# MCU_CTRL_MMR0_CFG0 register map
Vendor: Texas Instruments
Peripheral module from a debugger description file (folder J721S2).
Registers are 32-bit, read-write, reset 0x0 unless marked. A register's access mark holds for its fields unless they carry their own. Offsets are as the file gives them; lines under a group give offsets from that group; [hi:lo] are bit positions; {n}, {i} and the like mark numbered series; 'fields as' and 'values as' point back to an identical list; <NAME> marks a mode.

## MCU_CTRL_MMR0_CFG0 (part 1 of 2)
0x6060 CFG0_MCU_SPI1_CTRL_PROXY
  [0] MCU_SPI1_CTRL_SPI1_LINKDIS_PROXY — Disables direct connection of MCU_SPI1 to SPI3 Field values (others are reserved): 1'b0 - MCU_SPI1 is tied as a slave to SPI3. MCU_SPI1 CLK, DATA1 and CS0 are driven from SPI3, DATA OUT drives SPI3 DATA0 1'b1 - MCU_SPI1 is NOT tied as a slave to SPI3. MCU_SPI1 CLK, DATA0, DATA1 and CS[3:0] are controlled through their respective MCU_SPI1 pins and SPI3 CLK, DATA0, DATA1, and CS[3:0] are controlled through their respective SPI3 pins.
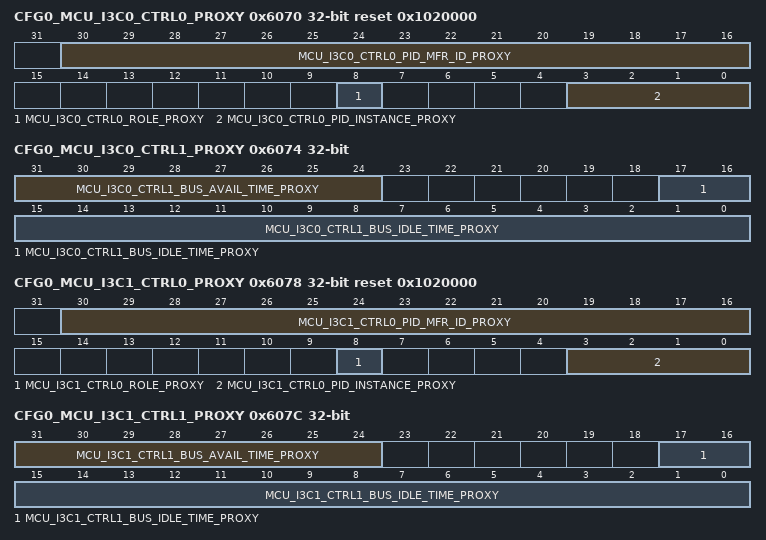
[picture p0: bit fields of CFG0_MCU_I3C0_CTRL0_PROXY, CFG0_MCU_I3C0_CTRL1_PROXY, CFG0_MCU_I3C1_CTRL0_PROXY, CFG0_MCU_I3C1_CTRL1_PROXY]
0x6070 CFG0_MCU_I3C0_CTRL0_PROXY reset 0x1020000
  [30:16] MCU_I3C0_CTRL0_PID_MFR_ID_PROXY — Manufacturer ID This input corresponds to bits[47:33] of the Provisional ID to identify the manufacturer. Defaults to TI value.
  [8] MCU_I3C0_CTRL0_ROLE_PROXY — Master Role 0 - Main master 1 - Secondary master
  [3:0] MCU_I3C0_CTRL0_PID_INSTANCE_PROXY — Provisional ID Instance. This input corresponds to bits[15:12] of the Provisional ID. It is intended to provide a way of differentiating several I3C devices if there would be no other way to have each manufactured device have a unique Provisional ID
0x6074 CFG0_MCU_I3C0_CTRL1_PROXY
  [31:24] MCU_I3C0_CTRL1_BUS_AVAIL_TIME_PROXY — Indicates the number of pclk cycles in the Bus Available condition
  [17:0] MCU_I3C0_CTRL1_BUS_IDLE_TIME_PROXY — Indicates the number of pclk cycles in the Bus Idle condition
0x6078 CFG0_MCU_I3C1_CTRL0_PROXY reset 0x1020000
  [30:16] MCU_I3C1_CTRL0_PID_MFR_ID_PROXY — Manufacturer ID This input corresponds to bits[47:33] of the Provisional ID to identify the manufacturer. Defaults to TI value.
  [8] MCU_I3C1_CTRL0_ROLE_PROXY — Master Role 0 - Main master 1 - Secondary master
  [3:0] MCU_I3C1_CTRL0_PID_INSTANCE_PROXY — Provisional ID Instance. This input corresponds to bits[15:12] of the Provisional ID. It is intended to provide a way of differentiating several I3C devices if there would be no other way to have each manufactured device have a unique Provisional ID
0x607C CFG0_MCU_I3C1_CTRL1_PROXY
  [31:24] MCU_I3C1_CTRL1_BUS_AVAIL_TIME_PROXY — Indicates the number of pclk cycles in the Bus Available condition
  [17:0] MCU_I3C1_CTRL1_BUS_IDLE_TIME_PROXY — Indicates the number of pclk cycles in the Bus Idle condition
0x6080 CFG0_MCU_I2C0_CTRL_PROXY
  [0] MCU_I2C0_CTRL_HS_MCS_EN_PROXY — HS Mode master current source enable. When set, enables the current-source pull-up on the SCL output. Only one master on the I2C bus should enable SCL current sourcing.
0x6084 CFG0_MCU_I2C1_CTRL_PROXY
  [0] MCU_I2C1_CTRL_HS_MCS_EN_PROXY — HS Mode master current source enable. When set, enables the current-source pull-up on the SCL output. Only one master on the I2C bus should enable SCL current sourcing.
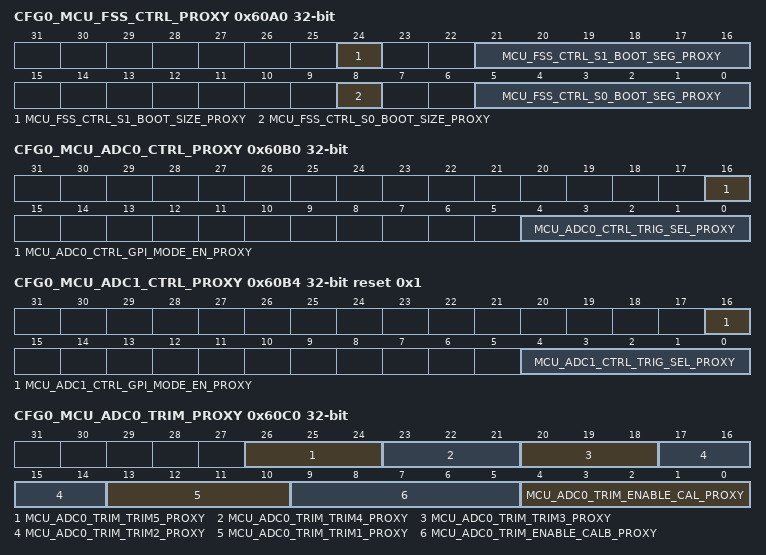
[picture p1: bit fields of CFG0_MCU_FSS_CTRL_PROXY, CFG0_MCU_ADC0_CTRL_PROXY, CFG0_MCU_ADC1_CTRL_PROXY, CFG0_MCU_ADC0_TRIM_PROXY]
0x60A0 CFG0_MCU_FSS_CTRL_PROXY
  [24] MCU_FSS_CTRL_S1_BOOT_SIZE_PROXY — Selects the size of the boot block to be used for the S1 (OSPI1) flash interface 0 - S1 boot size is 64 MB 1 - S1 boot size is 128 MB
  [21:16] MCU_FSS_CTRL_S1_BOOT_SEG_PROXY — Selects the boot block to be used for the S1 (OSPI1) flash interface. If the s1_boot_size is 128 MB then only bits [4:0] of this field are used. Care must be taken to account for the address translation as to not fall off or wrap the address of the flash. (e.g. if both ECC and authentication are enabled for 64 MB boot, the highest valid block number is 49, as sector 50 is only .2M Bytes in size.) 6'h00 - Use block 0 6'h01 - Use block 1 : 6'h3F - Use block 63
  [8] MCU_FSS_CTRL_S0_BOOT_SIZE_PROXY — Selects the size of the boot block to be used for the S0 (OSPI0 or Hyperbus) flash interface 0 - S0 boot size is 64 MB 1 - S0 boot size is 128 MB
  [5:0] MCU_FSS_CTRL_S0_BOOT_SEG_PROXY — Selects the boot block to be used for the S0 (OSPI0 or Hyperbus) flash interface. If the s0_boot_size is 128 MB then only bits [4:0] of this field are used. Care must be taken to account for the address translation as to not fall off or wrap the address of the flash. (e.g. if both ECC and authentication are enabled for 64 MB boot, the highest valid block number is 49, as sector 50 is only .2M Bytes in size.) 6'h00 - Use block 0 6'h01 - Use block 1 : 6'h3F - Use block 63
0x60B0 CFG0_MCU_ADC0_CTRL_PROXY
  [16] MCU_ADC0_CTRL_GPI_MODE_EN_PROXY — Enables MCU_ADC0 data pins to be used as general purpose inputs when set. This signal is tied to the en_dig_test input of MCU_ADC0
  [4:0] MCU_ADC0_CTRL_TRIG_SEL_PROXY — Selects the source of the ADC hardware event trigger Field values (others are reserved): 5'b00000 - MCU_ADC_EXT_TRIGGER0 pin 5'b00001 - MCU_ADC_EXT_TRIGGER1 pin 5'b00010 - eHRPWM SOCA event 5'b00011 - eHRPWM SOCB event 5'b00100 - MCU Timer0 PWM output 5'b00101 - MCU Timer1 PWM output 5'b00110 - MCU Timer2 PWM output 5'b00111 - MCU Timer3 PWM output 5'b01000 - Timer0 PWM output 5'b01001 - Timer1 PWM output 5'b01010 - Timer2 PWM output 5'b01011 - Timer3 PWM output 5'b01100 - Timer4 PWM output 5'b01101 - Timer5 PWM output 5'b01110 - Timer6 PWM output 5'b01111 - Timer7 PWM output 5'b10000 - Timer8 PWM output 5'b10001 - Timer9 PWM output 5'b10010 - Timer10 PWM output 5'b10011 - Timer11 PWM output undefined - undefined 5'b10101 - Reserved (tied 1'b0) undefined - undefined 5'b10110 - Reserved (tied 1'b0) undefined - undefined 5'b10111 - Reserved (tied 1'b0) undefined - undefined 5'b11000 - Reserved (tied 1'b0) 5'b11000 - MCU Timer4 PWM output 5'b11001 - MCU Timer5 PWM output 5'b11010 - MCU Timer6 PWM output 5'b11011 - MCU Timer7 PWM output 5'b11100 - MCU Timer8 PWM output 5'b11101 - MCU Timer9 PWM output 5'b11110 - Reserved (tied 1'b0) 5'b11111 - Reserved (tied 1'b0)
0x60B4 CFG0_MCU_ADC1_CTRL_PROXY reset 0x1
  [16] MCU_ADC1_CTRL_GPI_MODE_EN_PROXY — Enables MCU_ADC1 data pins to be used as general purpose inputs when set. This signal is tied to the en_dig_test input of MCU_ADC1
  [4:0] MCU_ADC1_CTRL_TRIG_SEL_PROXY — Selects the source of the ADC hardware event trigger Field values (others are reserved): 5'b00000 - MCU_ADC_EXT_TRIGGER0 pin 5'b00001 - MCU_ADC_EXT_TRIGGER1 pin 5'b00010 - eHRPWM SOCA event 5'b00011 - eHRPWM SOCB event 5'b00100 - MCU Timer0 PWM output 5'b00101 - MCU Timer1 PWM output 5'b00110 - MCU Timer2 PWM output 5'b00111 - MCU Timer3 PWM output 5'b01000 - Timer0 PWM output 5'b01001 - Timer1 PWM output 5'b01010 - Timer2 PWM output 5'b01011 - Timer3 PWM output 5'b01100 - Timer4 PWM output 5'b01101 - Timer5 PWM output 5'b01110 - Timer6 PWM output 5'b01111 - Timer7 PWM output 5'b10000 - Timer8 PWM output 5'b10001 - Timer9 PWM output 5'b10010 - Timer10 PWM output 5'b10011 - Timer11 PWM output undefined - undefined 5'b10101 - Reserved (tied 1'b0) undefined - undefined 5'b10110 - Reserved (tied 1'b0) undefined - undefined undefined - undefined 5'b11000 - MCU Timer4 PWM output 5'b11001 - MCU Timer5 PWM output 5'b11010 - MCU Timer6 PWM output 5'b11011 - MCU Timer7 PWM output 5'b11100 - MCU Timer8 PWM output 5'b11101 - MCU Timer9 PWM output 5'b11110 - Reserved (tied 1'b0) 5'b11111 - Reserved (tied 1'b0)
0x60C0 CFG0_MCU_ADC0_TRIM_PROXY
  [26:24] MCU_ADC0_TRIM_TRIM5_PROXY — Trim value for C5 0.37 fF to 3.2fF in ~0.37fF increments
  [23:21] MCU_ADC0_TRIM_TRIM4_PROXY — Trim value for C4 0.37 fF to 3.2fF in ~0.37fF increments
  [20:18] MCU_ADC0_TRIM_TRIM3_PROXY — Trim value for C3 0.37 fF to 3.2fF in ~0.37fF increments
  [17:14] MCU_ADC0_TRIM_TRIM2_PROXY — Trim value for C2 0.37 fF to 6.4fF in ~0.37fF increments
  [13:10] MCU_ADC0_TRIM_TRIM1_PROXY — Trim value for C1 0.37 fF to 6.4fF in ~0.37fF increments
  [9:5] MCU_ADC0_TRIM_ENABLE_CALB_PROXY — Reserved. This bitfield no longer used
  [4:0] MCU_ADC0_TRIM_ENABLE_CAL_PROXY — Reserved. This bitfield no longer used
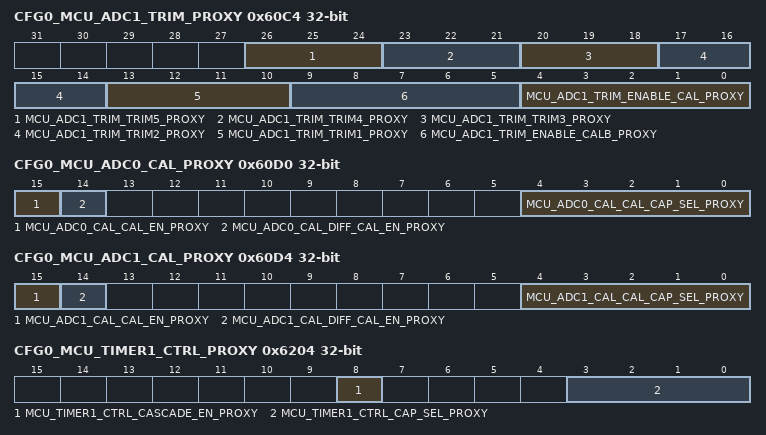
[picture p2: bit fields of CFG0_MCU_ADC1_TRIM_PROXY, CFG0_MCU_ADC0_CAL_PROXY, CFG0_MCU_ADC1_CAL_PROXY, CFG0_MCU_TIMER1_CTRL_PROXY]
0x60C4 CFG0_MCU_ADC1_TRIM_PROXY
  [26:24] MCU_ADC1_TRIM_TRIM5_PROXY — Trim value for C5 0.37 fF to 3.2fF in ~0.37fF increments
  [23:21] MCU_ADC1_TRIM_TRIM4_PROXY — Trim value for C4 0.37 fF to 3.2fF in ~0.37fF increments
  [20:18] MCU_ADC1_TRIM_TRIM3_PROXY — Trim value for C3 0.37 fF to 3.2fF in ~0.37fF increments
  [17:14] MCU_ADC1_TRIM_TRIM2_PROXY — Trim value for C2 0.37 fF to 6.4fF in ~0.37fF increments
  [13:10] MCU_ADC1_TRIM_TRIM1_PROXY — Trim value for C1 0.37 fF to 6.4fF in ~0.37fF increments
  [9:5] MCU_ADC1_TRIM_ENABLE_CALB_PROXY — Reserved. This bitfield no longer used
  [4:0] MCU_ADC1_TRIM_ENABLE_CAL_PROXY — Reserved. This bitfield no longer used
0x60D0 CFG0_MCU_ADC0_CAL_PROXY
  [15] MCU_ADC0_CAL_CAL_EN_PROXY — Enable single-ended calibration Set to 1 to begin single-ended calibration
  [14] MCU_ADC0_CAL_DIFF_CAL_EN_PROXY — Enable differential calibration Set to 1 to begin differential calibration
  [4:0] MCU_ADC0_CAL_CAL_CAP_SEL_PROXY — Select capacitor for calibration Bits correspond to C5:C1 Field values (others are reserved): 5'b00000 - None 5'b00001 - Select C1 5'b00010 - Select C2 5'b00100 - Select C3 5'b01000 - Select C4 5'b10000 - Select C5
0x60D4 CFG0_MCU_ADC1_CAL_PROXY
  [15] MCU_ADC1_CAL_CAL_EN_PROXY — Enable single-ended calibration Set to 1 to begin single-ended calibration
  [14] MCU_ADC1_CAL_DIFF_CAL_EN_PROXY — Enable differential calibration Set to 1 to begin differential calibration
  [4:0] MCU_ADC1_CAL_CAL_CAP_SEL_PROXY — Select capacitor for calibration Bits correspond to C5:C1 Field values (others are reserved): 5'b00000 - None 5'b00001 - Select C1 5'b00010 - Select C2 5'b00100 - Select C3 5'b01000 - Select C4 5'b10000 - Select C5
0x6200 CFG0_MCU_TIMER0_CTRL_PROXY
  [3:0] MCU_TIMER0_CTRL_CAP_SEL_PROXY — Selects the MCU_TIMERIO input pin for capture input signal. This control is only used when TIMER0 is configured for capture operation. Field values (others are reserved): 4'b0000 - Use MCU_TIMER_IO0 pin 4'b0001 - Use MCU_TIMER_IO1 pin 4'b0010 - Use MCU_TIMER_IO2 pin 4'b0011 - Use MCU_TIMER_IO3 pin 4'b0100 - Use MCU_TIMER_IO4 pin 4'b0101 - Use MCU_TIMER_IO5 pin 4'b0110 - Use MCU_TIMER_IO6 pin 4'b0111 - Use MCU_TIMER_IO7 pin 4'b1000 - Use MCU_TIMER_IO8 pin 4'b1001 - Use MCU_TIMER_IO9 pin
0x6204 CFG0_MCU_TIMER1_CTRL_PROXY
  [8] MCU_TIMER1_CTRL_CASCADE_EN_PROXY — When set, enables cascading of MCU_TIMER1 to MCU_TIMER0
  [3:0] MCU_TIMER1_CTRL_CAP_SEL_PROXY — Selects the MCU_TIMERIO input pin for capture input signal. This control is only used when TIMER1 is configured for capture operation. Field values (others are reserved): 4'b0000 - Use MCU_TIMER_IO0 pin 4'b0001 - Use MCU_TIMER_IO1 pin 4'b0010 - Use MCU_TIMER_IO2 pin 4'b0011 - Use MCU_TIMER_IO3 pin 4'b0100 - Use MCU_TIMER_IO4 pin 4'b0101 - Use MCU_TIMER_IO5 pin 4'b0110 - Use MCU_TIMER_IO6 pin 4'b0111 - Use MCU_TIMER_IO7 pin 4'b1000 - Use MCU_TIMER_IO8 pin 4'b1001 - Use MCU_TIMER_IO9 pin
0x6208 CFG0_MCU_TIMER2_CTRL_PROXY
  [3:0] MCU_TIMER2_CTRL_CAP_SEL_PROXY — Selects the MCU_TIMERIO input pin for capture input signal. This control is only used when TIMER2 is configured for capture operation. Field values (others are reserved): 4'b0000 - Use MCU_TIMER_IO0 pin 4'b0001 - Use MCU_TIMER_IO1 pin 4'b0010 - Use MCU_TIMER_IO2 pin 4'b0011 - Use MCU_TIMER_IO3 pin 4'b0100 - Use MCU_TIMER_IO4 pin 4'b0101 - Use MCU_TIMER_IO5 pin 4'b0110 - Use MCU_TIMER_IO6 pin 4'b0111 - Use MCU_TIMER_IO7 pin 4'b1000 - Use MCU_TIMER_IO8 pin 4'b1001 - Use MCU_TIMER_IO9 pin
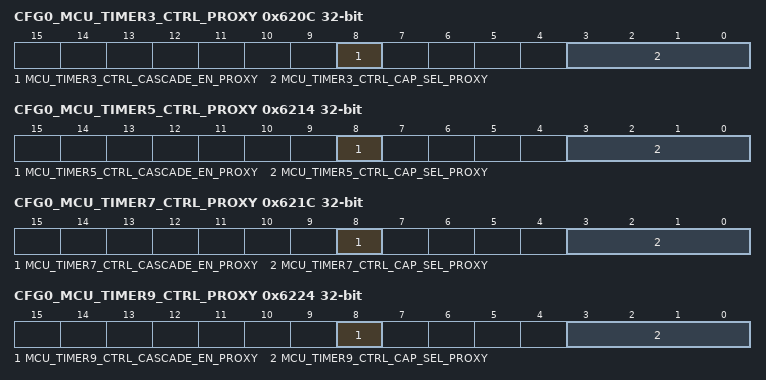
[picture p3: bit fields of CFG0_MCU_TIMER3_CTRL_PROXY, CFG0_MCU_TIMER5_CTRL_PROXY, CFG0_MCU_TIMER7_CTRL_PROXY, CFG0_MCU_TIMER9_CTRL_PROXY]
0x620C CFG0_MCU_TIMER3_CTRL_PROXY
  [8] MCU_TIMER3_CTRL_CASCADE_EN_PROXY — When set, enables cascading of MCU_TIMER3 to MCU_TIMER2
  [3:0] MCU_TIMER3_CTRL_CAP_SEL_PROXY — Selects the MCU_TIMERIO input pin for capture input signal. This control is only used when TIMER3 is configured for capture operation. Field values (others are reserved): 4'b0000 - Use MCU_TIMER_IO0 pin 4'b0001 - Use MCU_TIMER_IO1 pin 4'b0010 - Use MCU_TIMER_IO2 pin 4'b0011 - Use MCU_TIMER_IO3 pin 4'b0100 - Use MCU_TIMER_IO4 pin 4'b0101 - Use MCU_TIMER_IO5 pin 4'b0110 - Use MCU_TIMER_IO6 pin 4'b0111 - Use MCU_TIMER_IO7 pin 4'b1000 - Use MCU_TIMER_IO8 pin 4'b1001 - Use MCU_TIMER_IO9 pin
0x6210 CFG0_MCU_TIMER4_CTRL_PROXY
  [3:0] MCU_TIMER4_CTRL_CAP_SEL_PROXY — Selects the MCU_TIMERIO input pin for capture input signal. This control is only used when TIMER4 is configured for capture operation. Field values (others are reserved): 4'b0000 - Use MCU_TIMER_IO0 pin 4'b0001 - Use MCU_TIMER_IO1 pin 4'b0010 - Use MCU_TIMER_IO2 pin 4'b0011 - Use MCU_TIMER_IO3 pin 4'b0100 - Use MCU_TIMER_IO4 pin 4'b0101 - Use MCU_TIMER_IO5 pin 4'b0110 - Use MCU_TIMER_IO6 pin 4'b0111 - Use MCU_TIMER_IO7 pin 4'b1000 - Use MCU_TIMER_IO8 pin 4'b1001 - Use MCU_TIMER_IO9 pin
0x6214 CFG0_MCU_TIMER5_CTRL_PROXY
  [8] MCU_TIMER5_CTRL_CASCADE_EN_PROXY — When set, enables cascading of MCU_TIMER5 to MCU_TIMER4
  [3:0] MCU_TIMER5_CTRL_CAP_SEL_PROXY — Selects the MCU_TIMERIO input pin for capture input signal. This control is only used when TIMER5 is configured for capture operation. Field values (others are reserved): 4'b0000 - Use MCU_TIMER_IO0 pin 4'b0001 - Use MCU_TIMER_IO1 pin 4'b0010 - Use MCU_TIMER_IO2 pin 4'b0011 - Use MCU_TIMER_IO3 pin 4'b0100 - Use MCU_TIMER_IO4 pin 4'b0101 - Use MCU_TIMER_IO5 pin 4'b0110 - Use MCU_TIMER_IO6 pin 4'b0111 - Use MCU_TIMER_IO7 pin 4'b1000 - Use MCU_TIMER_IO8 pin 4'b1001 - Use MCU_TIMER_IO9 pin
0x6218 CFG0_MCU_TIMER6_CTRL_PROXY
  [3:0] MCU_TIMER6_CTRL_CAP_SEL_PROXY — Selects the MCU_TIMERIO input pin for capture input signal. This control is only used when TIMER6 is configured for capture operation. Field values (others are reserved): 4'b0000 - Use MCU_TIMER_IO0 pin 4'b0001 - Use MCU_TIMER_IO1 pin 4'b0010 - Use MCU_TIMER_IO2 pin 4'b0011 - Use MCU_TIMER_IO3 pin 4'b0100 - Use MCU_TIMER_IO4 pin 4'b0101 - Use MCU_TIMER_IO5 pin 4'b0110 - Use MCU_TIMER_IO6 pin 4'b0111 - Use MCU_TIMER_IO7 pin 4'b1000 - Use MCU_TIMER_IO8 pin 4'b1001 - Use MCU_TIMER_IO9 pin
0x621C CFG0_MCU_TIMER7_CTRL_PROXY
  [8] MCU_TIMER7_CTRL_CASCADE_EN_PROXY — When set, enables cascading of MCU_TIMER7 to MCU_TIMER6
  [3:0] MCU_TIMER7_CTRL_CAP_SEL_PROXY — Selects the MCU_TIMERIO input pin for capture input signal. This control is only used when TIMER7 is configured for capture operation. Field values (others are reserved): 4'b0000 - Use MCU_TIMER_IO0 pin 4'b0001 - Use MCU_TIMER_IO1 pin 4'b0010 - Use MCU_TIMER_IO2 pin 4'b0011 - Use MCU_TIMER_IO3 pin 4'b0100 - Use MCU_TIMER_IO4 pin 4'b0101 - Use MCU_TIMER_IO5 pin 4'b0110 - Use MCU_TIMER_IO6 pin 4'b0111 - Use MCU_TIMER_IO7 pin 4'b1000 - Use MCU_TIMER_IO8 pin 4'b1001 - Use MCU_TIMER_IO9 pin
0x6220 CFG0_MCU_TIMER8_CTRL_PROXY
  [3:0] MCU_TIMER8_CTRL_CAP_SEL_PROXY — Selects the MCU_TIMERIO input pin for capture input signal. This control is only used when TIMER8 is configured for capture operation. Field values (others are reserved): 4'b0000 - Use MCU_TIMER_IO0 pin 4'b0001 - Use MCU_TIMER_IO1 pin 4'b0010 - Use MCU_TIMER_IO2 pin 4'b0011 - Use MCU_TIMER_IO3 pin 4'b0100 - Use MCU_TIMER_IO4 pin 4'b0101 - Use MCU_TIMER_IO5 pin 4'b0110 - Use MCU_TIMER_IO6 pin 4'b0111 - Use MCU_TIMER_IO7 pin 4'b1000 - Use MCU_TIMER_IO8 pin 4'b1001 - Use MCU_TIMER_IO9 pin
0x6224 CFG0_MCU_TIMER9_CTRL_PROXY
  [8] MCU_TIMER9_CTRL_CASCADE_EN_PROXY — When set, enables cascading of MCU_TIMER9 to MCU_TIMER8
  [3:0] MCU_TIMER9_CTRL_CAP_SEL_PROXY — Selects the MCU_TIMERIO input pin for capture input signal. This control is only used when TIMER9 is configured for capture operation. Field values (others are reserved): 4'b0000 - Use MCU_TIMER_IO0 pin 4'b0001 - Use MCU_TIMER_IO1 pin 4'b0010 - Use MCU_TIMER_IO2 pin 4'b0011 - Use MCU_TIMER_IO3 pin 4'b0100 - Use MCU_TIMER_IO4 pin 4'b0101 - Use MCU_TIMER_IO5 pin 4'b0110 - Use MCU_TIMER_IO6 pin 4'b0111 - Use MCU_TIMER_IO7 pin 4'b1000 - Use MCU_TIMER_IO8 pin 4'b1001 - Use MCU_TIMER_IO9 pin
{0x6280+4i} CFG0_MCU_TIMERIO{i}_CTRL_PROXY reset 0xF (i=0..9)
  [3:0] MCU_TIMERIO{i}_CTRL_OUT_SEL_PROXY — Selects the source of the MCU_TIMERIO{i} output Field values (others are reserved): 4'b0000 - MCU_TIMERIO{i} is driven by MCU_TIMER0 output 4'b0001 - MCU_TIMERIO{i} is driven by MCU_TIMER1 output 4'b0010 - MCU_TIMERIO{i} is driven by MCU_TIMER2 output 4'b0011 - MCU_TIMERIO{i} is driven by MCU_TIMER3 output 4'b0100 - MCU_TIMERIO{i} is driven by MCU_TIMER4 output 4'b0101 - MCU_TIMERIO{i} is driven by MCU_TIMER5 output 4'b0110 - MCU_TIMERIO{i} is driven by MCU_TIMER6 output 4'b0111 - MCU_TIMERIO{i} is driven by MCU_TIMER7 output 4'b1000 - MCU_TIMERIO{i} is driven by MCU_TIMER8 output 4'b1001 - MCU_TIMERIO{i} is driven by MCU_TIMER9 output 4'b1010 - MCU_TIMERIO{i} is driven low 4'b1011 - MCU_TIMERIO{i} is driven high 4'b1100 - MCU_TIMERIO{i} is driven low 4'b1101 - MCU_TIMERIO{i} is driven high 4'b1110 - MCU_TIMERIO{i} is driven low 4'b1111 - MCU_TIMERIO{i} is driven high
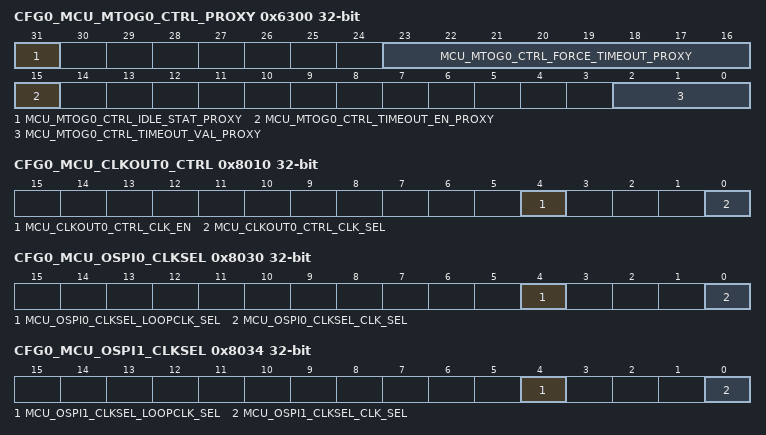
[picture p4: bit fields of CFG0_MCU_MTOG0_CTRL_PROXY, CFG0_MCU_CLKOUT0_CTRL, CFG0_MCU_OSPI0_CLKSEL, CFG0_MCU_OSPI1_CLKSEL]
0x6300 CFG0_MCU_MTOG0_CTRL_PROXY access per field
  [31] MCU_MTOG0_CTRL_IDLE_STAT_PROXY ro — Idle status When high, indicates MTOG0 is idle.
  [23:16] MCU_MTOG0_CTRL_FORCE_TIMEOUT_PROXY rw — Force Timeout Forces a flush of the interface transactions. This bitfield is only relevant if timeout_en=1. After forcing a timeout by writing the encoded value, the force_timeout and timeout_en bitfields must be cleared to clear the timeout before re-enabling the gasket. 8'h95 - Force a gasket timeout All others - Normal operation
  [15] MCU_MTOG0_CTRL_TIMEOUT_EN_PROXY rw — Timeout Enable 1'b0 - Disable the gasket. Clear the interrupt and reset the counter 1'b1 - Enable the timeout gasket functions
  [2:0] MCU_MTOG0_CTRL_TIMEOUT_VAL_PROXY rw — Gasket Timeout Value Selects the number of clock cycles before the interface is considered to have timed out Field values (others are reserved): 3'b000 - 1024 clock cycles 3'b001 - 4096 clock cycles 3'b010 - 16,384 clock cycles 3'b011 - 65,536 clock cycles 3'b100 - 262,144 clock cycles 3'b101 - 1,048,576 clock cycles 3'b110 - 2,097,152 clock cycles 3'b111 - 4,194,303 clock cycles
{0x7100+4i} CFG0_CLAIMREG_P1_R{i} (i=0..6)
  [31:0] CLAIMREG_P1_R{i} — Claim bits for Partition 1
0x8010 CFG0_MCU_CLKOUT0_CTRL
  [4] MCU_CLKOUT0_CTRL_CLK_EN — When set, enables MCU_CLKOUT0 output
  [0] MCU_CLKOUT0_CTRL_CLK_SEL — Selects MCU_CLKOUT0 clock source 1'b0 - RGMII_MHZ_50_CLK (50 MHz) 1'b1 -RGMII_MHZ_50_CLK / 2 (25 MHz)
0x8018 CFG0_MCU_EFUSE_CLKSEL
  [0] MCU_EFUSE_CLKSEL_CLK_SEL — Selects the clock source Field values (others are reserved): 1'b0 - EFUSE_CLK (HFOSC0_CLKOUT or CLK_12M_RC) 1'b1 - MCU_SYSCLK0 / 8
0x8020 CFG0_MCU_MCAN0_CLKSEL
  [1:0] MCU_MCAN0_CLKSEL_CLK_SEL — MCU_MCAN MCAN_CLK selection 2'b00 - MCU_PLL2_HSDIV3_CLKOUT 2'b01 - MCU_EXT_REFCLK0 2'b10 - MCU_PLL1_HSDIV2_CLKOUT 2'b11 - HFOSC0_CLKOUT
0x8024 CFG0_MCU_MCAN1_CLKSEL
  [1:0] MCU_MCAN1_CLKSEL_CLK_SEL — MCU_MCAN MCAN_CLK selection 2'b00 - MCU_PLL2_HSDIV3_CLKOUT 2'b01 - MCU_EXT_REFCLK0 2'b10 - MCU_PLL1_HSDIV2_CLKOUT 2'b11 - HFOSC0_CLKOUT
0x8030 CFG0_MCU_OSPI0_CLKSEL
  [4] MCU_OSPI0_CLKSEL_LOOPCLK_SEL — OBSPI0 Loopback clock source 1'b0 - OSPI_DQS external pin (external) 1'b1 - OSPI_LBCLKO output (internal)
  [0] MCU_OSPI0_CLKSEL_CLK_SEL — OSPI0 reference clock selection 1'b0 - MCU_PLL1_HSDIV4_CLKOUT 1'b1 - MCU_PLL2_HSDIV4_CLKOUT
0x8034 CFG0_MCU_OSPI1_CLKSEL
  [4] MCU_OSPI1_CLKSEL_LOOPCLK_SEL — OBSPI1 Loopback clock source 1'b0 - OSPI_DQS external pin (external) 1'b1 - OSPI_LBCLKO output (internal)
  [0] MCU_OSPI1_CLKSEL_CLK_SEL — OSPI1 reference clock selection 1'b0 - MCU_PLL1_HSDIV4_CLKOUT 1'b1 - MCU_PLL2_HSDIV4_CLKOUT
0x8040 CFG0_MCU_ADC0_CLKSEL
  [1:0] MCU_ADC0_CLKSEL_CLK_SEL — Selects the sampling clock source for ADC0 Field values (others are reserved): 2'b00 - HFOSC0_CLKOUT 2'b01 - MCU_PLL1_HSDIV1_CLKOUT1 2'b10 - MCU_PLL0_HSDIV1_CLKOUT1 2'b11 - MCU_EXT_REFCLK0
0x8044 CFG0_MCU_ADC1_CLKSEL
  [1:0] MCU_ADC1_CLKSEL_CLK_SEL — Selects the sampling clock source for ADC1 Field values (others are reserved): 2'b00 - HFOSC0_CLKOUT 2'b01 - MCU_PLL1_HSDIV1_CLKOUT1 2'b10 - MCU_PLL0_HSDIV1_CLKOUT1 2'b11 - MCU_EXT_REFCLK0
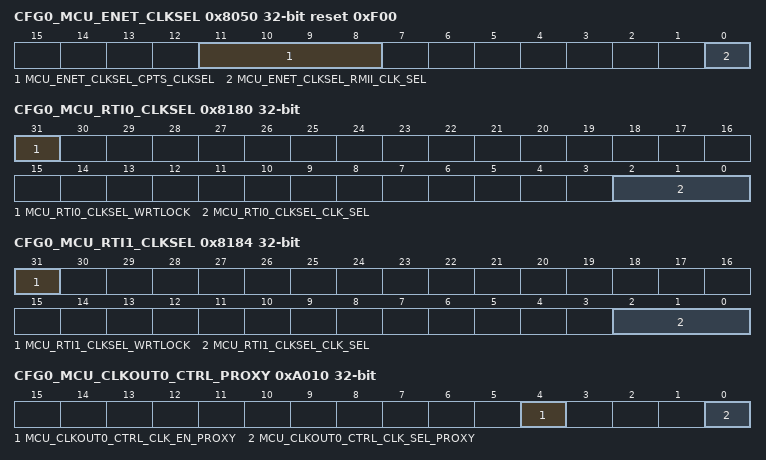
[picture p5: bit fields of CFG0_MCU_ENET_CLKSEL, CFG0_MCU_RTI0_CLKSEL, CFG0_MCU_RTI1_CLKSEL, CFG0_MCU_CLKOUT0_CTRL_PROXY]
0x8050 CFG0_MCU_ENET_CLKSEL reset 0xF00
  [11:8] MCU_ENET_CLKSEL_CPTS_CLKSEL — Selects the clock source for the CPSW2x Ethernet switch Common Platform Time Stamp module Field values (others are reserved): 4'b0000 - MAIN_PLL3_HSDIV1_CLKOUT 4'b0001 - MAIN_PLL0_HSDIV6_CLKOUT 4'b0010 - MCU_CPTS_REF_CLK (pin) 4'b0011 - CPTS_RFT_CLK (pin) 4'b0100 - MCU_EXT_REFCLK0 (pin) 4'b0101 - EXT_REFCLK1 (pin) 4'b0110 - SERDES0_IP2_LN0_TXMCLK 4'b0111 - SERDES0_IP2_LN1_TXMCLK undefined - undefined 4'b1000 - SERDES0_IP2_LN2_TXMCLK undefined - undefined 4'b1001 - SERDES0_IP2_LN3_TXMCLK undefined - undefined undefined - undefined undefined - undefined 4'b1010 - SERDES1_IP2_LN0_TXMCLK undefined - undefined undefined - undefined undefined - undefined 4'b1011 - SERDES1_IP2_LN1_TXMCLK undefined - undefined undefined - undefined undefined - undefined 4'b1100 - SERDES1_IP2_LN2_TXMCLK undefined - undefined undefined - undefined undefined - undefined 4'b1101 - SERDES1_IP2_LN3_TXMCLK 4'b1110 - MCU_PLL2_HSDIV1_CLKOUT undefined - undefined 4'b1111 - MAIN_SYSCLK0 / 2
  [0] MCU_ENET_CLKSEL_RMII_CLK_SEL — Selects the rmii clock (rmii_mhz_50_clk) source. This defaults to the internal 50 MHz clock source for proper clockstop operation 1'b0 - MCU_PLL2_HSDIV0_CLKOUT / 5 1'b1 - MCU_RMII_REFCLK (pin)
0x8080 CFG0_MCU_R5_CORE0_CLKSEL
  [0] MCU_R5_CORE0_CLKSEL_CLK_SEL — Selects the Core 0 functional clock and mcu/interface clock ratio. Note, this value must only be changed when the MCU R5 is powered off or in WFI 1'b0 - Use MCU_SYSCLK0. MCU/interface is 3:1 clock ratio 1'b1 - Use MCU_SYSCLK0/3. MCU/interface is 1:1 clock ratio
0x8084 CFG0_MCU_R5_CORE1_CLKSEL
  [0] MCU_R5_CORE1_CLKSEL_CLK_SEL — Selects the Core 1 functional clock and mcu/interface clock ratio. Note, this value must only be changed when the MCU R5 is powered off or in WFI 1'b0 - Use MCU_SYSCLK0. MCU/interface is 3:1 clock ratio 1'b1 - Use MCU_SYSCLK0/3. MCU/interface is 1:1 clock ratio
{0x8100+4i} CFG0_MCU_TIMER{i}_CLKSEL (i=0..9)
  [2:0] MCU_TIMER{i}_CLKSEL_CLK_SEL — Timer functional clock input select mux control Field values (others are reserved): 3'b000 - HFOSC0_CLKOUT 3'b001 - MCU_SYSCLK0 / 4 3'b010 - CLK_12M_RC 3'b011 - MCU_PLL2_HSDIV2_CLKOUT 3'b100 - MCU_EXT_REFCLK0 3'b101 - LFXOSC_CLKOUT 3'b110 - CPSW_GENF0 3'b111 - CLK_32K
0x8180 CFG0_MCU_RTI0_CLKSEL
  [31] MCU_RTI0_CLKSEL_WRTLOCK — When set, locks further writes to MCU_RTI0_CLKSEL until the next module reset
  [2:0] MCU_RTI0_CLKSEL_CLK_SEL — RTI functional clock input select mux control Field values (others are reserved): 2'b00 - HFOSC0_CLKOUT 2'b01 - LFXOSC_CLKOUT 2'b10 - CLK_12M_RC 2'b11 - CLK_32K
0x8184 CFG0_MCU_RTI1_CLKSEL
  [31] MCU_RTI1_CLKSEL_WRTLOCK — When set, locks further writes to MCU_RTI1_CLKSEL until the next module reset
  [2:0] MCU_RTI1_CLKSEL_CLK_SEL — RTI functional clock input select mux control Field values (others are reserved): 2'b00 - HFOSC0_CLKOUT 2'b01 - LFXOSC_CLKOUT 2'b10 - CLK_12M_RC 2'b11 - CLK_32K
0x81C0 CFG0_MCU_USART_CLKSEL
  [0] MCU_USART_CLKSEL_CLK_SEL — MCU_USART0 FCLK selection 1'b0 - MCU_PLL1_HSDIV3_CLKOUT 1'b1 - MAIN_PLL1_HSDIV5_CLKOUT
{0x9100+4i} CFG0_CLAIMREG_P2_R{i}_READONLY ro (i=0..3)
  [31:0] CLAIMREG_P2_R{i}_READONLY — Claim bits for Partition 2
0xA010 CFG0_MCU_CLKOUT0_CTRL_PROXY
  [4] MCU_CLKOUT0_CTRL_CLK_EN_PROXY — When set, enables MCU_CLKOUT0 output
  [0] MCU_CLKOUT0_CTRL_CLK_SEL_PROXY — Selects MCU_CLKOUT0 clock source 1'b0 - RGMII_MHZ_50_CLK (50 MHz) 1'b1 -RGMII_MHZ_50_CLK / 2 (25 MHz)
0xA018 CFG0_MCU_EFUSE_CLKSEL_PROXY
  [0] MCU_EFUSE_CLKSEL_CLK_SEL_PROXY — Selects the clock source Field values (others are reserved): 1'b0 - EFUSE_CLK (HFOSC0_CLKOUT or CLK_12M_RC) 1'b1 - MCU_SYSCLK0 / 8
0xA020 CFG0_MCU_MCAN0_CLKSEL_PROXY
  [1:0] MCU_MCAN0_CLKSEL_CLK_SEL_PROXY — MCU_MCAN MCAN_CLK selection 2'b00 - MCU_PLL2_HSDIV3_CLKOUT 2'b01 - MCU_EXT_REFCLK0 2'b10 - MCU_PLL1_HSDIV2_CLKOUT 2'b11 - HFOSC0_CLKOUT
0xA024 CFG0_MCU_MCAN1_CLKSEL_PROXY
  [1:0] MCU_MCAN1_CLKSEL_CLK_SEL_PROXY — MCU_MCAN MCAN_CLK selection 2'b00 - MCU_PLL2_HSDIV3_CLKOUT 2'b01 - MCU_EXT_REFCLK0 2'b10 - MCU_PLL1_HSDIV2_CLKOUT 2'b11 - HFOSC0_CLKOUT
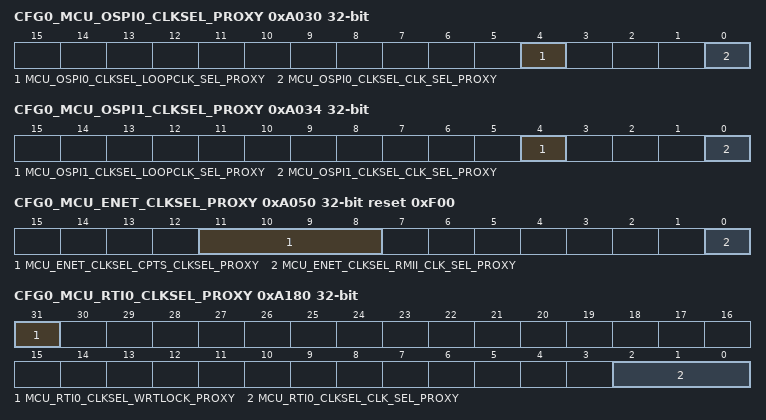
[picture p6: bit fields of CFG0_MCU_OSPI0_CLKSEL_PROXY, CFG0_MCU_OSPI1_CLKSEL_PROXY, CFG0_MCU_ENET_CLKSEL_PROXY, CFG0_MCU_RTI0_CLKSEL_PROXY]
0xA030 CFG0_MCU_OSPI0_CLKSEL_PROXY
  [4] MCU_OSPI0_CLKSEL_LOOPCLK_SEL_PROXY — OBSPI0 Loopback clock source 1'b0 - OSPI_DQS external pin (external) 1'b1 - OSPI_LBCLKO output (internal)
  [0] MCU_OSPI0_CLKSEL_CLK_SEL_PROXY — OSPI0 reference clock selection 1'b0 - MCU_PLL1_HSDIV4_CLKOUT 1'b1 - MCU_PLL2_HSDIV4_CLKOUT
0xA034 CFG0_MCU_OSPI1_CLKSEL_PROXY
  [4] MCU_OSPI1_CLKSEL_LOOPCLK_SEL_PROXY — OBSPI1 Loopback clock source 1'b0 - OSPI_DQS external pin (external) 1'b1 - OSPI_LBCLKO output (internal)
  [0] MCU_OSPI1_CLKSEL_CLK_SEL_PROXY — OSPI1 reference clock selection 1'b0 - MCU_PLL1_HSDIV4_CLKOUT 1'b1 - MCU_PLL2_HSDIV4_CLKOUT
0xA040 CFG0_MCU_ADC0_CLKSEL_PROXY
  [1:0] MCU_ADC0_CLKSEL_CLK_SEL_PROXY — Selects the sampling clock source for ADC0 Field values (others are reserved): 2'b00 - HFOSC0_CLKOUT 2'b01 - MCU_PLL1_HSDIV1_CLKOUT1 2'b10 - MCU_PLL0_HSDIV1_CLKOUT1 2'b11 - MCU_EXT_REFCLK0
0xA044 CFG0_MCU_ADC1_CLKSEL_PROXY
  [1:0] MCU_ADC1_CLKSEL_CLK_SEL_PROXY — Selects the sampling clock source for ADC1 Field values (others are reserved): 2'b00 - HFOSC0_CLKOUT 2'b01 - MCU_PLL1_HSDIV1_CLKOUT1 2'b10 - MCU_PLL0_HSDIV1_CLKOUT1 2'b11 - MCU_EXT_REFCLK0
0xA050 CFG0_MCU_ENET_CLKSEL_PROXY reset 0xF00
  [11:8] MCU_ENET_CLKSEL_CPTS_CLKSEL_PROXY — Selects the clock source for the CPSW2x Ethernet switch Common Platform Time Stamp module Field values (others are reserved): 4'b0000 - MAIN_PLL3_HSDIV1_CLKOUT 4'b0001 - MAIN_PLL0_HSDIV6_CLKOUT 4'b0010 - MCU_CPTS_REF_CLK (pin) 4'b0011 - CPTS_RFT_CLK (pin) 4'b0100 - MCU_EXT_REFCLK0 (pin) 4'b0101 - EXT_REFCLK1 (pin) 4'b0110 - SERDES0_IP2_LN0_TXMCLK 4'b0111 - SERDES0_IP2_LN1_TXMCLK undefined - undefined 4'b1000 - SERDES0_IP2_LN2_TXMCLK undefined - undefined 4'b1001 - SERDES0_IP2_LN3_TXMCLK undefined - undefined undefined - undefined undefined - undefined 4'b1010 - SERDES1_IP2_LN0_TXMCLK undefined - undefined undefined - undefined undefined - undefined 4'b1011 - SERDES1_IP2_LN1_TXMCLK undefined - undefined undefined - undefined undefined - undefined 4'b1100 - SERDES1_IP2_LN2_TXMCLK undefined - undefined undefined - undefined undefined - undefined 4'b1101 - SERDES1_IP2_LN3_TXMCLK 4'b1110 - MCU_PLL2_HSDIV1_CLKOUT undefined - undefined 4'b1111 - MAIN_SYSCLK0 / 2
  [0] MCU_ENET_CLKSEL_RMII_CLK_SEL_PROXY — Selects the rmii clock (rmii_mhz_50_clk) source. This defaults to the internal 50 MHz clock source for proper clockstop operation 1'b0 - MCU_PLL2_HSDIV0_CLKOUT / 5 1'b1 - MCU_RMII_REFCLK (pin)
0xA080 CFG0_MCU_R5_CORE0_CLKSEL_PROXY
  [0] MCU_R5_CORE0_CLKSEL_CLK_SEL_PROXY — Selects the Core 0 functional clock and mcu/interface clock ratio. Note, this value must only be changed when the MCU R5 is powered off or in WFI 1'b0 - Use MCU_SYSCLK0. MCU/interface is 3:1 clock ratio 1'b1 - Use MCU_SYSCLK0/3. MCU/interface is 1:1 clock ratio
0xA084 CFG0_MCU_R5_CORE1_CLKSEL_PROXY
  [0] MCU_R5_CORE1_CLKSEL_CLK_SEL_PROXY — Selects the Core 1 functional clock and mcu/interface clock ratio. Note, this value must only be changed when the MCU R5 is powered off or in WFI 1'b0 - Use MCU_SYSCLK0. MCU/interface is 3:1 clock ratio 1'b1 - Use MCU_SYSCLK0/3. MCU/interface is 1:1 clock ratio
{0xA100+4i} CFG0_MCU_TIMER{i}_CLKSEL_PROXY (i=0..9)
  [2:0] MCU_TIMER{i}_CLKSEL_CLK_SEL_PROXY — Timer functional clock input select mux control Field values (others are reserved): 3'b000 - HFOSC0_CLKOUT 3'b001 - MCU_SYSCLK0 / 4 3'b010 - CLK_12M_RC 3'b011 - MCU_PLL2_HSDIV2_CLKOUT 3'b100 - MCU_EXT_REFCLK0 3'b101 - LFXOSC_CLKOUT 3'b110 - CPSW_GENF0 3'b111 - CLK_32K
0xA180 CFG0_MCU_RTI0_CLKSEL_PROXY
  [31] MCU_RTI0_CLKSEL_WRTLOCK_PROXY — When set, locks further writes to MCU_RTI0_CLKSEL until the next module reset
  [2:0] MCU_RTI0_CLKSEL_CLK_SEL_PROXY — RTI functional clock input select mux control Field values (others are reserved): 2'b00 - HFOSC0_CLKOUT 2'b01 - LFXOSC_CLKOUT 2'b10 - CLK_12M_RC 2'b11 - CLK_32K
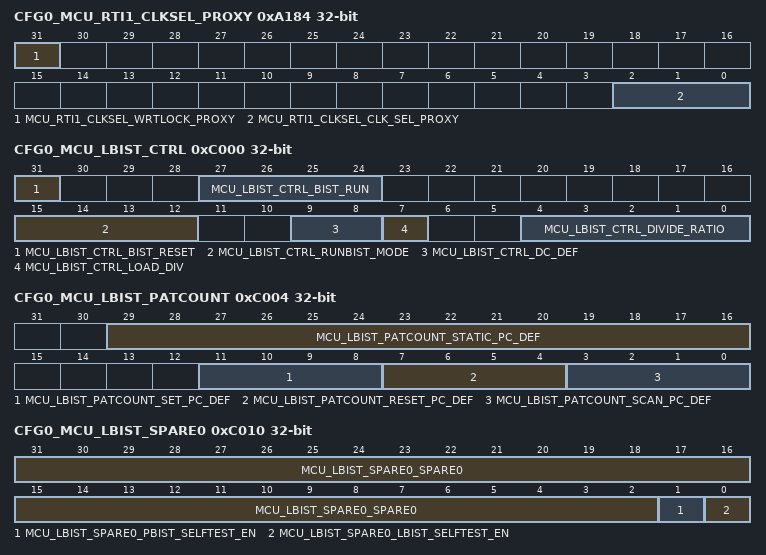
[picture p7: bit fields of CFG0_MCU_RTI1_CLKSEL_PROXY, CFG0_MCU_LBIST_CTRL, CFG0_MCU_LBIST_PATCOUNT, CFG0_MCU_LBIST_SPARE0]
0xA184 CFG0_MCU_RTI1_CLKSEL_PROXY
  [31] MCU_RTI1_CLKSEL_WRTLOCK_PROXY — When set, locks further writes to MCU_RTI1_CLKSEL until the next module reset
  [2:0] MCU_RTI1_CLKSEL_CLK_SEL_PROXY — RTI functional clock input select mux control Field values (others are reserved): 2'b00 - HFOSC0_CLKOUT 2'b01 - LFXOSC_CLKOUT 2'b10 - CLK_12M_RC 2'b11 - CLK_32K
0xA1C0 CFG0_MCU_USART_CLKSEL_PROXY
  [0] MCU_USART_CLKSEL_CLK_SEL_PROXY — MCU_USART0 FCLK selection 1'b0 - MCU_PLL1_HSDIV3_CLKOUT 1'b1 - MAIN_PLL1_HSDIV5_CLKOUT
{0xB100+4i} CFG0_CLAIMREG_P2_R{i} (i=0..3)
  [31:0] CLAIMREG_P2_R{i} — Claim bits for Partition 2
0xC000 CFG0_MCU_LBIST_CTRL
  [31] MCU_LBIST_CTRL_BIST_RESET — Reset LBIST macro (active low)
  [27:24] MCU_LBIST_CTRL_BIST_RUN — Starts LBIST if all bits are 1
  [15:12] MCU_LBIST_CTRL_RUNBIST_MODE — Runbist mode enable if all bits are 1
  [9:8] MCU_LBIST_CTRL_DC_DEF — Clock delay after scan_enable switching
  [7] MCU_LBIST_CTRL_LOAD_DIV — Loads LBIST clock divide ratio on transition from 0 to 1
  [4:0] MCU_LBIST_CTRL_DIVIDE_RATIO — LBIST clock divide ratio
0xC004 CFG0_MCU_LBIST_PATCOUNT
  [29:16] MCU_LBIST_PATCOUNT_STATIC_PC_DEF — Number of stuck-at patterns to run
  [11:8] MCU_LBIST_PATCOUNT_SET_PC_DEF — Number of set patterns to run
  [7:4] MCU_LBIST_PATCOUNT_RESET_PC_DEF — Number of reset patterns to run
  [3:0] MCU_LBIST_PATCOUNT_SCAN_PC_DEF — Number of chain test patterns to run
0xC008 CFG0_MCU_LBIST_SEED0
  [31:0] MCU_LBIST_SEED0_PRPG_DEF — Initial seed for PRPG (bits 31:0)
0xC00C CFG0_MCU_LBIST_SEED1
  [20:0] MCU_LBIST_SEED1_PRPG_DEF — Initial seed for PRPG (bits 52:32)
0xC010 CFG0_MCU_LBIST_SPARE0
  [31:2] MCU_LBIST_SPARE0_SPARE0 — LBIST spare bits
  [1] MCU_LBIST_SPARE0_PBIST_SELFTEST_EN — PBIST isolation control
  [0] MCU_LBIST_SPARE0_LBIST_SELFTEST_EN — LBIST isolation control
0xC014 CFG0_MCU_LBIST_SPARE1
  [31:0] MCU_LBIST_SPARE1_SPARE1 — LBIST spare bits
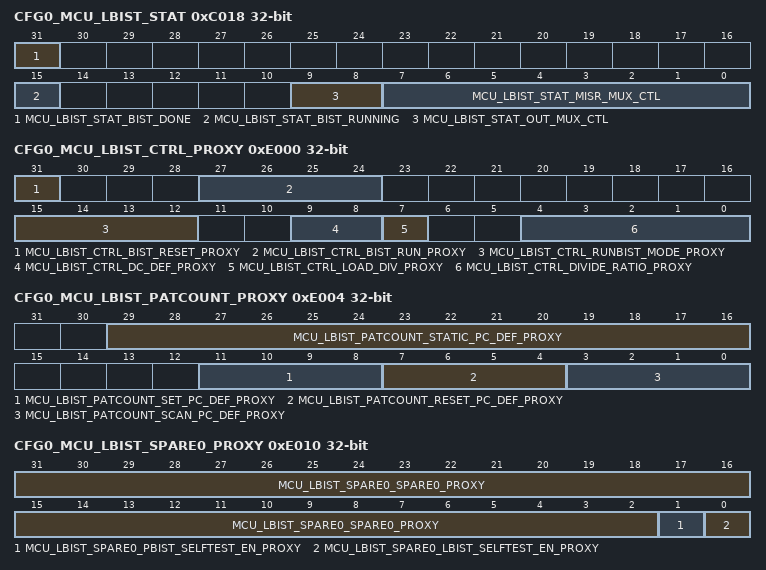
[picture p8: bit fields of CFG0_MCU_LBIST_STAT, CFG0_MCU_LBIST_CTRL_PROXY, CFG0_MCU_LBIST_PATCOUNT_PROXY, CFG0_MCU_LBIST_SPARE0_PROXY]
0xC018 CFG0_MCU_LBIST_STAT access per field
  [31] MCU_LBIST_STAT_BIST_DONE ro — LBIST is done
  [15] MCU_LBIST_STAT_BIST_RUNNING ro — LBIST is running
  [9:8] MCU_LBIST_STAT_OUT_MUX_CTL rw — Selects source of LBIST output 00 - LBIST IP PID value 01 - LBIST CTRL ID value 1x - MISR value
  [7:0] MCU_LBIST_STAT_MISR_MUX_CTL rw — Selects block of 32 MISR bits to read. A value of 0 selects a compacted 32-bit version of the full MISR. A value of 1-32 select a 32-bit segment of the MISR.
0xC01C CFG0_MCU_LBIST_MISR ro
  [31:0] MCU_LBIST_MISR_MISR_RESULT — 32-bits of MISR value selected by misr_mux_ctl
0xC280 CFG0_MCU_LBIST_SIG ro
  [31:0] MCU_LBIST_SIG_MISR_SIG — MISR signature
{0xD100+4i} CFG0_CLAIMREG_P3_R{i}_READONLY ro (i=0..5)
  [31:0] CLAIMREG_P3_R{i}_READONLY — Claim bits for Partition 3
0xE000 CFG0_MCU_LBIST_CTRL_PROXY
  [31] MCU_LBIST_CTRL_BIST_RESET_PROXY — Reset LBIST macro (active low)
  [27:24] MCU_LBIST_CTRL_BIST_RUN_PROXY — Starts LBIST if all bits are 1
  [15:12] MCU_LBIST_CTRL_RUNBIST_MODE_PROXY — Runbist mode enable if all bits are 1
  [9:8] MCU_LBIST_CTRL_DC_DEF_PROXY — Clock delay after scan_enable switching
  [7] MCU_LBIST_CTRL_LOAD_DIV_PROXY — Loads LBIST clock divide ratio on transition from 0 to 1
  [4:0] MCU_LBIST_CTRL_DIVIDE_RATIO_PROXY — LBIST clock divide ratio
0xE004 CFG0_MCU_LBIST_PATCOUNT_PROXY
  [29:16] MCU_LBIST_PATCOUNT_STATIC_PC_DEF_PROXY — Number of stuck-at patterns to run
  [11:8] MCU_LBIST_PATCOUNT_SET_PC_DEF_PROXY — Number of set patterns to run
  [7:4] MCU_LBIST_PATCOUNT_RESET_PC_DEF_PROXY — Number of reset patterns to run
  [3:0] MCU_LBIST_PATCOUNT_SCAN_PC_DEF_PROXY — Number of chain test patterns to run
0xE008 CFG0_MCU_LBIST_SEED0_PROXY
  [31:0] MCU_LBIST_SEED0_PRPG_DEF_PROXY — Initial seed for PRPG (bits 31:0)
0xE00C CFG0_MCU_LBIST_SEED1_PROXY
  [20:0] MCU_LBIST_SEED1_PRPG_DEF_PROXY — Initial seed for PRPG (bits 52:32)
0xE010 CFG0_MCU_LBIST_SPARE0_PROXY
  [31:2] MCU_LBIST_SPARE0_SPARE0_PROXY — LBIST spare bits
  [1] MCU_LBIST_SPARE0_PBIST_SELFTEST_EN_PROXY — PBIST isolation control
  [0] MCU_LBIST_SPARE0_LBIST_SELFTEST_EN_PROXY — LBIST isolation control
0xE014 CFG0_MCU_LBIST_SPARE1_PROXY
  [31:0] MCU_LBIST_SPARE1_SPARE1_PROXY — LBIST spare bits
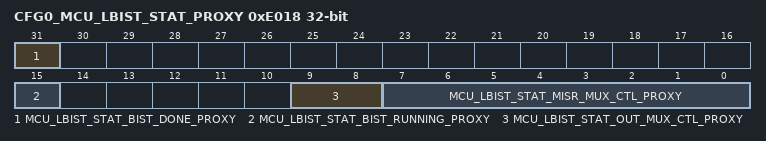
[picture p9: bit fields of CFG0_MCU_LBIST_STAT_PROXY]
0xE018 CFG0_MCU_LBIST_STAT_PROXY access per field
  [31] MCU_LBIST_STAT_BIST_DONE_PROXY ro — LBIST is done
  [15] MCU_LBIST_STAT_BIST_RUNNING_PROXY ro — LBIST is running
  [9:8] MCU_LBIST_STAT_OUT_MUX_CTL_PROXY rw — Selects source of LBIST output 00 - LBIST IP PID value 01 - LBIST CTRL ID value 1x - MISR value
  [7:0] MCU_LBIST_STAT_MISR_MUX_CTL_PROXY rw — Selects block of 32 MISR bits to read. A value of 0 selects a compacted 32-bit version of the full MISR. A value of 1-32 select a 32-bit segment of the MISR.
0xE01C CFG0_MCU_LBIST_MISR_PROXY ro
  [31:0] MCU_LBIST_MISR_MISR_RESULT_PROXY — 32-bits of MISR value selected by misr_mux_ctl
0xE280 CFG0_MCU_LBIST_SIG_PROXY ro
  [31:0] MCU_LBIST_SIG_MISR_SIG_PROXY — MISR signature
{0xF100+4i} CFG0_CLAIMREG_P3_R{i} (i=0..5)
  [31:0] CLAIMREG_P3_R{i} — Claim bits for Partition 3
{0x10000+4i} CFG0_DV_REG{i} (i=0..7)
  [31:0] DV_REG{i}_BIT — Defined by DV usage
{0x10200+4i} CFG0_DV_REG{i}_SET access not given (i=0..3)
  [31:0] DV_REG{i}_SET_BIT — Defined by DV usage (access R/W1TS)
{0x10300+4i} CFG0_DV_REG{i}_CLR access not given (i=0..3)
  [31:0] DV_REG{i}_CLR_BIT — Defined by DV usage (access R/W1TC)
{0x11100+4i} CFG0_CLAIMREG_P4_R{i}_READONLY ro (i=0..6)
  [31:0] CLAIMREG_P4_R{i}_READONLY — Claim bits for Partition 4
{0x12000+4i} CFG0_DV_REG{i}_PROXY (i=0..7)
  [31:0] DV_REG{i}_BIT_PROXY — Defined by DV usage
{0x12200+4i} CFG0_DV_REG{i}_SET_PROXY access not given (i=0..3)
  [31:0] DV_REG{i}_SET_BIT_PROXY — Defined by DV usage (access R/W1TS)
{0x12300+4i} CFG0_DV_REG{i}_CLR_PROXY access not given (i=0..3)
  [31:0] DV_REG{i}_CLR_BIT_PROXY — Defined by DV usage (access R/W1TC)
{0x13100+4i} CFG0_CLAIMREG_P4_R{i} (i=0..6)
  [31:0] CLAIMREG_P4_R{i} — Claim bits for Partition 4
